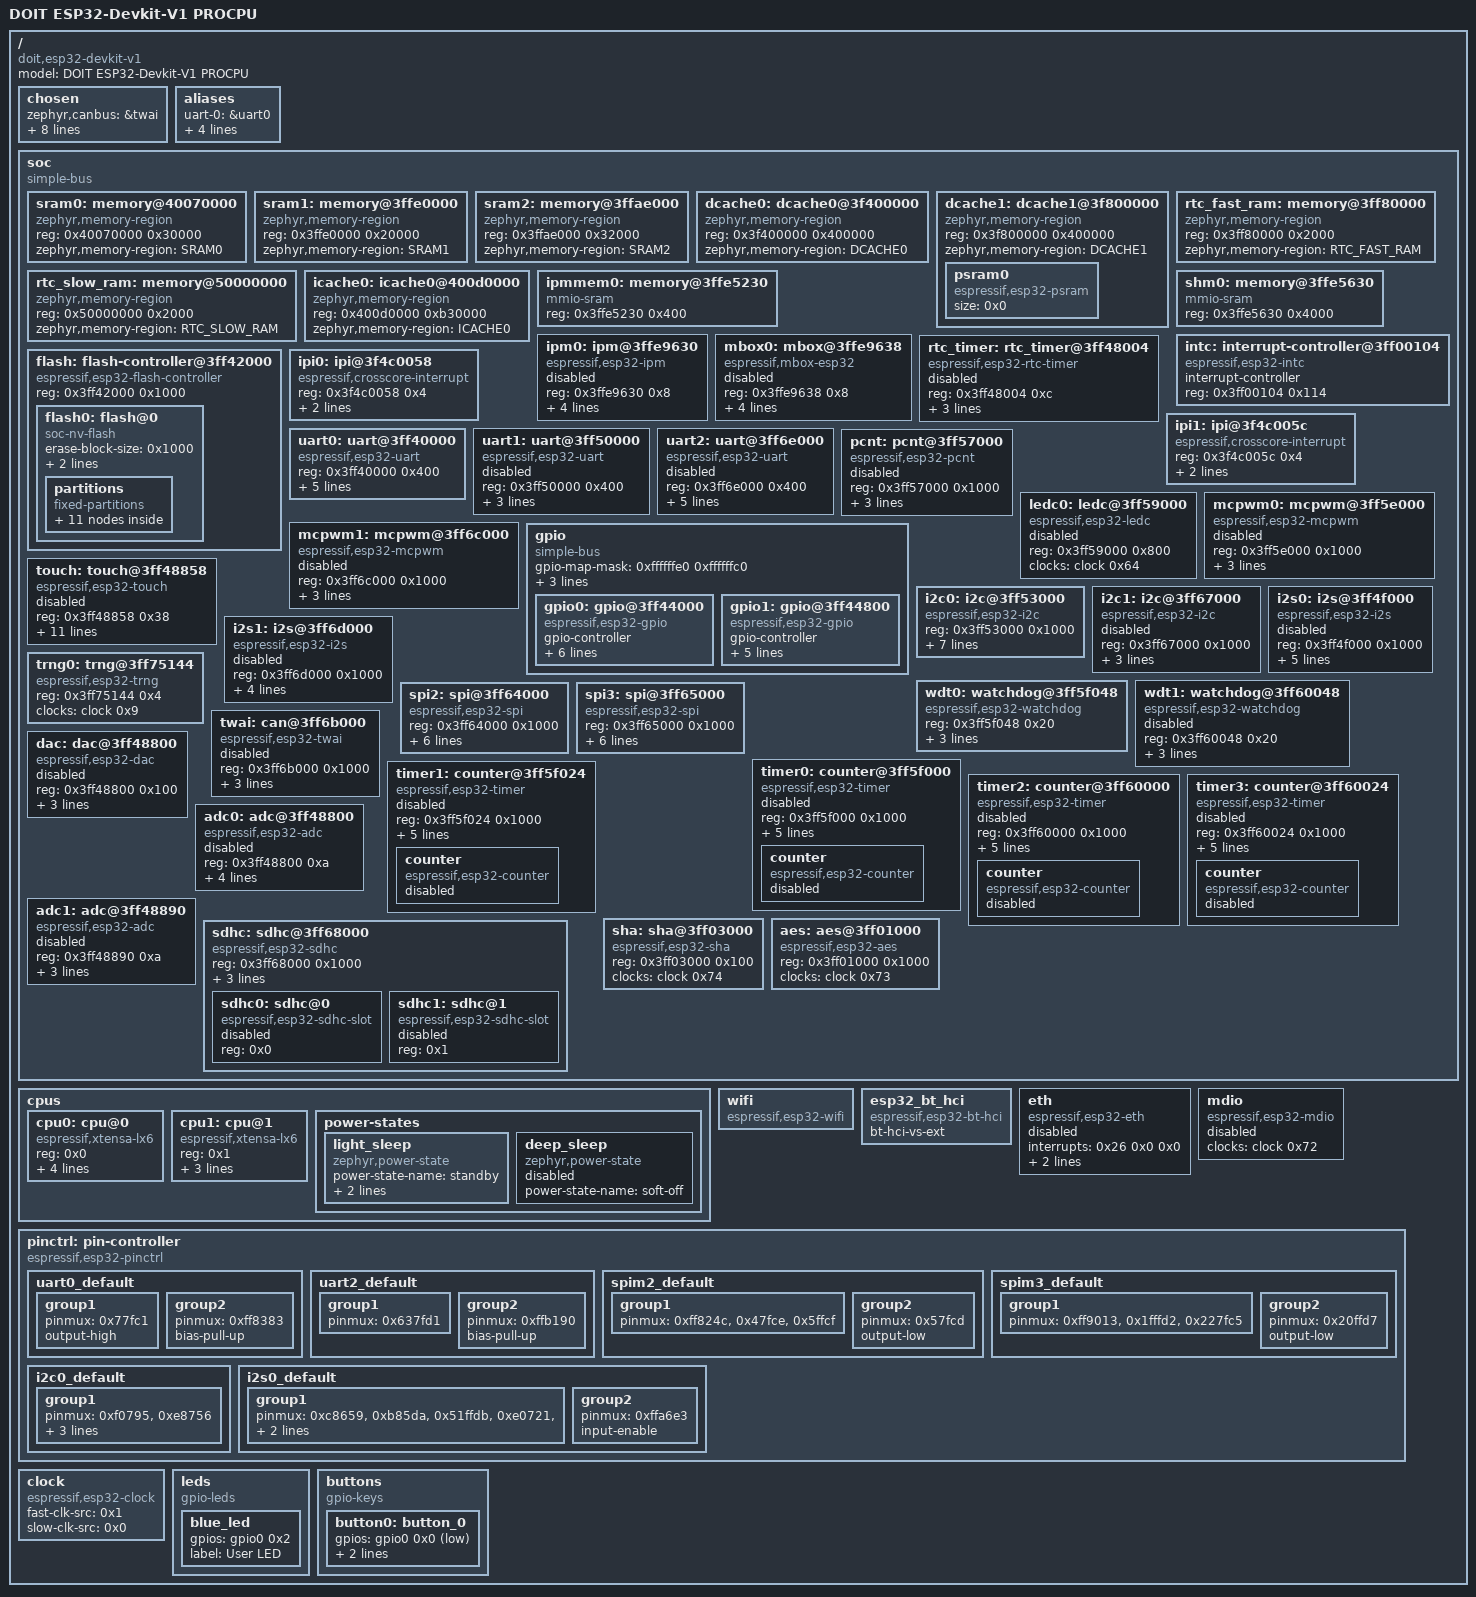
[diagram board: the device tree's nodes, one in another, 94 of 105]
/dts-v1/;

/* node '/' defined in zephyr/dts/common/skeleton.dtsi:9 */
/ {
	#address-cells = < 0x1 >;              /* in zephyr/dts/common/skeleton.dtsi:10 */
	#size-cells = < 0x1 >;                 /* in zephyr/dts/common/skeleton.dtsi:11 */
	model = "DOIT ESP32-Devkit-V1 PROCPU"; /* in zephyr/boards/others/doit_esp32_devkit_v1/doit_esp32_devkit_v1_procpu.dts:15 */
	compatible = "doit,esp32-devkit-v1";   /* in zephyr/boards/others/doit_esp32_devkit_v1/doit_esp32_devkit_v1_procpu.dts:16 */

	/* node '/chosen' defined in zephyr/dts/common/skeleton.dtsi:13 */
	chosen {
		zephyr,canbus = &twai;                    /* in zephyr/dts/xtensa/espressif/esp32/esp32_common.dtsi:20 */
		zephyr,entropy = &trng0;                  /* in zephyr/dts/xtensa/espressif/esp32/esp32_common.dtsi:21 */
		zephyr,flash-controller = &flash;         /* in zephyr/dts/xtensa/espressif/esp32/esp32_common.dtsi:22 */
		zephyr,sram = &sram1;                     /* in zephyr/boards/others/doit_esp32_devkit_v1/doit_esp32_devkit_v1_procpu.dts:46 */
		zephyr,console = &uart0;                  /* in zephyr/boards/others/doit_esp32_devkit_v1/doit_esp32_devkit_v1_procpu.dts:47 */
		zephyr,shell-uart = &uart0;               /* in zephyr/boards/others/doit_esp32_devkit_v1/doit_esp32_devkit_v1_procpu.dts:48 */
		zephyr,flash = &flash0;                   /* in zephyr/boards/others/doit_esp32_devkit_v1/doit_esp32_devkit_v1_procpu.dts:49 */
		zephyr,code-partition = &slot0_partition; /* in zephyr/boards/others/doit_esp32_devkit_v1/doit_esp32_devkit_v1_procpu.dts:50 */
		zephyr,bt-hci = &esp32_bt_hci;            /* in zephyr/boards/others/doit_esp32_devkit_v1/doit_esp32_devkit_v1_procpu.dts:51 */
	};

	/* node '/aliases' defined in zephyr/dts/common/skeleton.dtsi:15 */
	aliases {
		uart-0 = &uart0;   /* in zephyr/boards/others/doit_esp32_devkit_v1/doit_esp32_devkit_v1_procpu.dts:19 */
		i2c-0 = &i2c0;     /* in zephyr/boards/others/doit_esp32_devkit_v1/doit_esp32_devkit_v1_procpu.dts:20 */
		sw0 = &button0;    /* in zephyr/boards/others/doit_esp32_devkit_v1/doit_esp32_devkit_v1_procpu.dts:21 */
		led0 = &blue_led;  /* in zephyr/boards/others/doit_esp32_devkit_v1/doit_esp32_devkit_v1_procpu.dts:22 */
		watchdog0 = &wdt0; /* in zephyr/boards/others/doit_esp32_devkit_v1/doit_esp32_devkit_v1_procpu.dts:23 */
	};

	/* node '/soc' defined in zephyr/dts/xtensa/xtensa.dtsi:10 */
	soc {
		#address-cells = < 0x1 >;  /* in zephyr/dts/xtensa/xtensa.dtsi:11 */
		#size-cells = < 0x1 >;     /* in zephyr/dts/xtensa/xtensa.dtsi:12 */
		compatible = "simple-bus"; /* in zephyr/dts/xtensa/xtensa.dtsi:13 */
		ranges;                    /* in zephyr/dts/xtensa/xtensa.dtsi:14 */

		/* node '/soc/memory@40070000' defined in zephyr/dts/xtensa/espressif/esp32/esp32_common.dtsi:109 */
		sram0: memory@40070000 {
			compatible = "zephyr,memory-region",
			             "mmio-sram";            /* in zephyr/dts/xtensa/espressif/esp32/esp32_common.dtsi:110 */
			reg = < 0x40070000 0x30000 >;        /* in zephyr/dts/xtensa/espressif/esp32/esp32_common.dtsi:111 */
			zephyr,memory-region = "SRAM0";      /* in zephyr/dts/xtensa/espressif/esp32/esp32_common.dtsi:112 */
		};

		/* node '/soc/memory@3ffe0000' defined in zephyr/dts/xtensa/espressif/esp32/esp32_common.dtsi:115 */
		sram1: memory@3ffe0000 {
			compatible = "zephyr,memory-region",
			             "mmio-sram";            /* in zephyr/dts/xtensa/espressif/esp32/esp32_common.dtsi:116 */
			reg = < 0x3ffe0000 0x20000 >;        /* in zephyr/dts/xtensa/espressif/esp32/esp32_common.dtsi:117 */
			zephyr,memory-region = "SRAM1";      /* in zephyr/dts/xtensa/espressif/esp32/esp32_common.dtsi:118 */
		};

		/* node '/soc/memory@3ffae000' defined in zephyr/dts/xtensa/espressif/esp32/esp32_common.dtsi:121 */
		sram2: memory@3ffae000 {
			compatible = "zephyr,memory-region",
			             "mmio-sram";            /* in zephyr/dts/xtensa/espressif/esp32/esp32_common.dtsi:122 */
			reg = < 0x3ffae000 0x32000 >;        /* in zephyr/dts/xtensa/espressif/esp32/esp32_common.dtsi:123 */
			zephyr,memory-region = "SRAM2";      /* in zephyr/dts/xtensa/espressif/esp32/esp32_common.dtsi:124 */
		};

		/* node '/soc/dcache0@3f400000' defined in zephyr/dts/xtensa/espressif/esp32/esp32_common.dtsi:127 */
		dcache0: dcache0@3f400000 {
			compatible = "zephyr,memory-region",
			             "mmio-sram";            /* in zephyr/dts/xtensa/espressif/esp32/esp32_common.dtsi:128 */
			reg = < 0x3f400000 0x400000 >;       /* in zephyr/dts/xtensa/espressif/esp32/esp32_common.dtsi:129 */
			zephyr,memory-region = "DCACHE0";    /* in zephyr/dts/xtensa/espressif/esp32/esp32_common.dtsi:130 */
		};

		/* node '/soc/dcache1@3f800000' defined in zephyr/dts/xtensa/espressif/esp32/esp32_common.dtsi:133 */
		dcache1: dcache1@3f800000 {
			compatible = "zephyr,memory-region",
			             "mmio-sram";            /* in zephyr/dts/xtensa/espressif/esp32/esp32_common.dtsi:134 */
			reg = < 0x3f800000 0x400000 >;       /* in zephyr/dts/xtensa/espressif/esp32/esp32_common.dtsi:135 */
			zephyr,memory-region = "DCACHE1";    /* in zephyr/dts/xtensa/espressif/esp32/esp32_common.dtsi:136 */

			/* node '/soc/dcache1@3f800000/psram0' defined in zephyr/dts/xtensa/espressif/esp32/esp32_common.dtsi:138 */
			psram0: psram0 {
				compatible = "espressif,esp32-psram"; /* in zephyr/dts/xtensa/espressif/esp32/esp32_common.dtsi:139 */
				size = < 0x0 >;                       /* in zephyr/dts/xtensa/espressif/esp32/esp32_common.dtsi:140 */
			};
		};

		/* node '/soc/memory@3ff80000' defined in zephyr/dts/xtensa/espressif/esp32/esp32_common.dtsi:144 */
		rtc_fast_ram: memory@3ff80000 {
			compatible = "zephyr,memory-region",
			             "mmio-sram";              /* in zephyr/dts/xtensa/espressif/esp32/esp32_common.dtsi:145 */
			reg = < 0x3ff80000 0x2000 >;           /* in zephyr/dts/xtensa/espressif/esp32/esp32_common.dtsi:146 */
			zephyr,memory-region = "RTC_FAST_RAM"; /* in zephyr/dts/xtensa/espressif/esp32/esp32_common.dtsi:147 */
		};

		/* node '/soc/memory@50000000' defined in zephyr/dts/xtensa/espressif/esp32/esp32_common.dtsi:150 */
		rtc_slow_ram: memory@50000000 {
			compatible = "zephyr,memory-region",
			             "mmio-sram";              /* in zephyr/dts/xtensa/espressif/esp32/esp32_common.dtsi:151 */
			reg = < 0x50000000 0x2000 >;           /* in zephyr/dts/xtensa/espressif/esp32/esp32_common.dtsi:152 */
			zephyr,memory-region = "RTC_SLOW_RAM"; /* in zephyr/dts/xtensa/espressif/esp32/esp32_common.dtsi:153 */
		};

		/* node '/soc/icache0@400d0000' defined in zephyr/dts/xtensa/espressif/esp32/esp32_common.dtsi:156 */
		icache0: icache0@400d0000 {
			compatible = "zephyr,memory-region",
			             "mmio-sram";            /* in zephyr/dts/xtensa/espressif/esp32/esp32_common.dtsi:157 */
			reg = < 0x400d0000 0xb30000 >;       /* in zephyr/dts/xtensa/espressif/esp32/esp32_common.dtsi:158 */
			zephyr,memory-region = "ICACHE0";    /* in zephyr/dts/xtensa/espressif/esp32/esp32_common.dtsi:159 */
		};

		/* node '/soc/memory@3ffe5230' defined in zephyr/dts/xtensa/espressif/esp32/esp32_common.dtsi:162 */
		ipmmem0: memory@3ffe5230 {
			compatible = "mmio-sram";   /* in zephyr/dts/xtensa/espressif/esp32/esp32_common.dtsi:163 */
			reg = < 0x3ffe5230 0x400 >; /* in zephyr/dts/xtensa/espressif/esp32/esp32_common.dtsi:164 */
			phandle = < 0x1 >;          /* in zephyr/dts/xtensa/espressif/esp32/esp32_common.dtsi:176 */
		};

		/* node '/soc/memory@3ffe5630' defined in zephyr/dts/xtensa/espressif/esp32/esp32_common.dtsi:167 */
		shm0: memory@3ffe5630 {
			compatible = "mmio-sram";    /* in zephyr/dts/xtensa/espressif/esp32/esp32_common.dtsi:168 */
			reg = < 0x3ffe5630 0x4000 >; /* in zephyr/dts/xtensa/espressif/esp32/esp32_common.dtsi:169 */
		};

		/* node '/soc/ipm@3ffe9630' defined in zephyr/dts/xtensa/espressif/esp32/esp32_common.dtsi:172 */
		ipm0: ipm@3ffe9630 {
			compatible = "espressif,esp32-ipm"; /* in zephyr/dts/xtensa/espressif/esp32/esp32_common.dtsi:173 */
			reg = < 0x3ffe9630 0x8 >;           /* in zephyr/dts/xtensa/espressif/esp32/esp32_common.dtsi:174 */
			status = "disabled";                /* in zephyr/dts/xtensa/espressif/esp32/esp32_common.dtsi:175 */
			shared-memory = < &ipmmem0 >;       /* in zephyr/dts/xtensa/espressif/esp32/esp32_common.dtsi:176 */
			shared-memory-size = < 0x400 >;     /* in zephyr/dts/xtensa/espressif/esp32/esp32_common.dtsi:177 */
			interrupts = < 0x18 0x0 0x0 >,
			             < 0x19 0x0 0x0 >;      /* in zephyr/dts/xtensa/espressif/esp32/esp32_common.dtsi:178 */
			interrupt-parent = < &intc >;       /* in zephyr/dts/xtensa/espressif/esp32/esp32_common.dtsi:180 */
		};

		/* node '/soc/mbox@3ffe9638' defined in zephyr/dts/xtensa/espressif/esp32/esp32_common.dtsi:183 */
		mbox0: mbox@3ffe9638 {
			compatible = "espressif,mbox-esp32"; /* in zephyr/dts/xtensa/espressif/esp32/esp32_common.dtsi:184 */
			reg = < 0x3ffe9638 0x8 >;            /* in zephyr/dts/xtensa/espressif/esp32/esp32_common.dtsi:185 */
			status = "disabled";                 /* in zephyr/dts/xtensa/espressif/esp32/esp32_common.dtsi:186 */
			shared-memory = < &ipmmem0 >;        /* in zephyr/dts/xtensa/espressif/esp32/esp32_common.dtsi:187 */
			shared-memory-size = < 0x400 >;      /* in zephyr/dts/xtensa/espressif/esp32/esp32_common.dtsi:188 */
			interrupts = < 0x18 0x0 0x0 >,
			             < 0x19 0x0 0x0 >;       /* in zephyr/dts/xtensa/espressif/esp32/esp32_common.dtsi:189 */
			interrupt-parent = < &intc >;        /* in zephyr/dts/xtensa/espressif/esp32/esp32_common.dtsi:191 */
			#mbox-cells = < 0x1 >;               /* in zephyr/dts/xtensa/espressif/esp32/esp32_common.dtsi:192 */
		};

		/* node '/soc/interrupt-controller@3ff00104' defined in zephyr/dts/xtensa/espressif/esp32/esp32_common.dtsi:195 */
		intc: interrupt-controller@3ff00104 {
			#interrupt-cells = < 0x3 >;          /* in zephyr/dts/xtensa/espressif/esp32/esp32_common.dtsi:196 */
			#address-cells = < 0x0 >;            /* in zephyr/dts/xtensa/espressif/esp32/esp32_common.dtsi:197 */
			compatible = "espressif,esp32-intc"; /* in zephyr/dts/xtensa/espressif/esp32/esp32_common.dtsi:198 */
			interrupt-controller;                /* in zephyr/dts/xtensa/espressif/esp32/esp32_common.dtsi:199 */
			reg = < 0x3ff00104 0x114 >;          /* in zephyr/dts/xtensa/espressif/esp32/esp32_common.dtsi:200 */
			status = "okay";                     /* in zephyr/dts/xtensa/espressif/esp32/esp32_common.dtsi:201 */
			phandle = < 0x2 >;                   /* in zephyr/dts/xtensa/espressif/esp32/esp32_common.dtsi:180 */
		};

		/* node '/soc/rtc_timer@3ff48004' defined in zephyr/dts/xtensa/espressif/esp32/esp32_common.dtsi:204 */
		rtc_timer: rtc_timer@3ff48004 {
			reg = < 0x3ff48004 0xc >;                 /* in zephyr/dts/xtensa/espressif/esp32/esp32_common.dtsi:205 */
			compatible = "espressif,esp32-rtc-timer"; /* in zephyr/dts/xtensa/espressif/esp32/esp32_common.dtsi:206 */
			clocks = < &clock 0xf >;                  /* in zephyr/dts/xtensa/espressif/esp32/esp32_common.dtsi:207 */
			interrupts = < 0x2e 0x0 0x0 >;            /* in zephyr/dts/xtensa/espressif/esp32/esp32_common.dtsi:208 */
			interrupt-parent = < &intc >;             /* in zephyr/dts/xtensa/espressif/esp32/esp32_common.dtsi:209 */
			status = "disabled";                      /* in zephyr/dts/xtensa/espressif/esp32/esp32_common.dtsi:210 */
		};

		/* node '/soc/flash-controller@3ff42000' defined in zephyr/dts/xtensa/espressif/esp32/esp32_common.dtsi:213 */
		flash: flash-controller@3ff42000 {
			compatible = "espressif,esp32-flash-controller"; /* in zephyr/dts/xtensa/espressif/esp32/esp32_common.dtsi:214 */
			reg = < 0x3ff42000 0x1000 >;                     /* in zephyr/dts/xtensa/espressif/esp32/esp32_common.dtsi:215 */
			#address-cells = < 0x1 >;                        /* in zephyr/dts/xtensa/espressif/esp32/esp32_common.dtsi:216 */
			#size-cells = < 0x1 >;                           /* in zephyr/dts/xtensa/espressif/esp32/esp32_common.dtsi:217 */

			/* node '/soc/flash-controller@3ff42000/flash@0' defined in zephyr/dts/xtensa/espressif/esp32/esp32_common.dtsi:219 */
			flash0: flash@0 {
				compatible = "soc-nv-flash";   /* in zephyr/dts/xtensa/espressif/esp32/esp32_common.dtsi:220 */
				erase-block-size = < 0x1000 >; /* in zephyr/dts/xtensa/espressif/esp32/esp32_common.dtsi:221 */
				write-block-size = < 0x4 >;    /* in zephyr/dts/xtensa/espressif/esp32/esp32_common.dtsi:222 */
				reg = < 0x0 0x400000 >;        /* in zephyr/dts/xtensa/espressif/esp32/esp32_wroom_32ue_n4.dtsi:21 */

				/* node '/soc/flash-controller@3ff42000/flash@0/partitions' defined in zephyr/dts/vendor/espressif/partitions_0x1000_amp_4M.dtsi:8 */
				partitions {
					compatible = "fixed-partitions"; /* in zephyr/dts/vendor/espressif/partitions_0x1000_amp_4M.dtsi:9 */
					#address-cells = < 0x1 >;        /* in zephyr/dts/vendor/espressif/partitions_0x1000_amp_4M.dtsi:10 */
					#size-cells = < 0x1 >;           /* in zephyr/dts/vendor/espressif/partitions_0x1000_amp_4M.dtsi:11 */

					/* node '/soc/flash-controller@3ff42000/flash@0/partitions/partition@1000' defined in zephyr/dts/vendor/espressif/partitions_0x1000_amp_4M.dtsi:13 */
					boot_partition: partition@1000 {
						label = "mcuboot";       /* in zephyr/dts/vendor/espressif/partitions_0x1000_amp_4M.dtsi:14 */
						reg = < 0x1000 0xf000 >; /* in zephyr/dts/vendor/espressif/partitions_0x1000_amp_4M.dtsi:15 */
					};

					/* node '/soc/flash-controller@3ff42000/flash@0/partitions/partition@10000' defined in zephyr/dts/vendor/espressif/partitions_0x1000_amp_4M.dtsi:18 */
					sys_partition: partition@10000 {
						label = "sys";             /* in zephyr/dts/vendor/espressif/partitions_0x1000_amp_4M.dtsi:19 */
						reg = < 0x10000 0x10000 >; /* in zephyr/dts/vendor/espressif/partitions_0x1000_amp_4M.dtsi:20 */
					};

					/* node '/soc/flash-controller@3ff42000/flash@0/partitions/partition@20000' defined in zephyr/dts/vendor/espressif/partitions_0x1000_amp_4M.dtsi:23 */
					slot0_partition: partition@20000 {
						label = "image-0";          /* in zephyr/dts/vendor/espressif/partitions_0x1000_amp_4M.dtsi:24 */
						reg = < 0x20000 0x150000 >; /* in zephyr/dts/vendor/espressif/partitions_0x1000_amp_4M.dtsi:25 */
					};

					/* node '/soc/flash-controller@3ff42000/flash@0/partitions/partition@170000' defined in zephyr/dts/vendor/espressif/partitions_0x1000_amp_4M.dtsi:28 */
					slot1_partition: partition@170000 {
						label = "image-1";           /* in zephyr/dts/vendor/espressif/partitions_0x1000_amp_4M.dtsi:29 */
						reg = < 0x170000 0x150000 >; /* in zephyr/dts/vendor/espressif/partitions_0x1000_amp_4M.dtsi:30 */
					};

					/* node '/soc/flash-controller@3ff42000/flash@0/partitions/partition@2c0000' defined in zephyr/dts/vendor/espressif/partitions_0x1000_amp_4M.dtsi:33 */
					slot0_appcpu_partition: partition@2c0000 {
						label = "image-0-appcpu";   /* in zephyr/dts/vendor/espressif/partitions_0x1000_amp_4M.dtsi:34 */
						reg = < 0x2c0000 0x70000 >; /* in zephyr/dts/vendor/espressif/partitions_0x1000_amp_4M.dtsi:35 */
					};

					/* node '/soc/flash-controller@3ff42000/flash@0/partitions/partition@330000' defined in zephyr/dts/vendor/espressif/partitions_0x1000_amp_4M.dtsi:38 */
					slot1_appcpu_partition: partition@330000 {
						label = "image-1-appcpu";   /* in zephyr/dts/vendor/espressif/partitions_0x1000_amp_4M.dtsi:39 */
						reg = < 0x330000 0x70000 >; /* in zephyr/dts/vendor/espressif/partitions_0x1000_amp_4M.dtsi:40 */
					};

					/* node '/soc/flash-controller@3ff42000/flash@0/partitions/partition@3a0000' defined in zephyr/dts/vendor/espressif/partitions_0x1000_amp_4M.dtsi:43 */
					slot0_lpcore_partition: partition@3a0000 {
						label = "image-0-lpcore";  /* in zephyr/dts/vendor/espressif/partitions_0x1000_amp_4M.dtsi:44 */
						reg = < 0x3a0000 0x8000 >; /* in zephyr/dts/vendor/espressif/partitions_0x1000_amp_4M.dtsi:45 */
					};

					/* node '/soc/flash-controller@3ff42000/flash@0/partitions/partition@3a8000' defined in zephyr/dts/vendor/espressif/partitions_0x1000_amp_4M.dtsi:48 */
					slot1_lpcore_partition: partition@3a8000 {
						label = "image-1-lpcore";  /* in zephyr/dts/vendor/espressif/partitions_0x1000_amp_4M.dtsi:49 */
						reg = < 0x3a8000 0x8000 >; /* in zephyr/dts/vendor/espressif/partitions_0x1000_amp_4M.dtsi:50 */
					};

					/* node '/soc/flash-controller@3ff42000/flash@0/partitions/partition@3b0000' defined in zephyr/dts/vendor/espressif/partitions_0x1000_amp_4M.dtsi:53 */
					storage_partition: partition@3b0000 {
						label = "storage";          /* in zephyr/dts/vendor/espressif/partitions_0x1000_amp_4M.dtsi:54 */
						reg = < 0x3b0000 0x30000 >; /* in zephyr/dts/vendor/espressif/partitions_0x1000_amp_4M.dtsi:55 */
					};

					/* node '/soc/flash-controller@3ff42000/flash@0/partitions/partition@3e0000' defined in zephyr/dts/vendor/espressif/partitions_0x1000_amp_4M.dtsi:58 */
					scratch_partition: partition@3e0000 {
						label = "image-scratch";    /* in zephyr/dts/vendor/espressif/partitions_0x1000_amp_4M.dtsi:59 */
						reg = < 0x3e0000 0x1f000 >; /* in zephyr/dts/vendor/espressif/partitions_0x1000_amp_4M.dtsi:60 */
					};

					/* node '/soc/flash-controller@3ff42000/flash@0/partitions/partition@3ff000' defined in zephyr/dts/vendor/espressif/partitions_0x1000_amp_4M.dtsi:63 */
					coredump_partition: partition@3ff000 {
						label = "coredump";        /* in zephyr/dts/vendor/espressif/partitions_0x1000_amp_4M.dtsi:64 */
						reg = < 0x3ff000 0x1000 >; /* in zephyr/dts/vendor/espressif/partitions_0x1000_amp_4M.dtsi:65 */
					};
				};
			};
		};

		/* node '/soc/ipi@3f4c0058' defined in zephyr/dts/xtensa/espressif/esp32/esp32_common.dtsi:227 */
		ipi0: ipi@3f4c0058 {
			compatible = "espressif,crosscore-interrupt"; /* in zephyr/dts/xtensa/espressif/esp32/esp32_common.dtsi:228 */
			reg = < 0x3f4c0058 0x4 >;                     /* in zephyr/dts/xtensa/espressif/esp32/esp32_common.dtsi:229 */
			interrupts = < 0x18 0x0 0x0 >;                /* in zephyr/dts/xtensa/espressif/esp32/esp32_common.dtsi:230 */
			interrupt-parent = < &intc >;                 /* in zephyr/dts/xtensa/espressif/esp32/esp32_common.dtsi:231 */
		};

		/* node '/soc/ipi@3f4c005c' defined in zephyr/dts/xtensa/espressif/esp32/esp32_common.dtsi:234 */
		ipi1: ipi@3f4c005c {
			compatible = "espressif,crosscore-interrupt"; /* in zephyr/dts/xtensa/espressif/esp32/esp32_common.dtsi:235 */
			reg = < 0x3f4c005c 0x4 >;                     /* in zephyr/dts/xtensa/espressif/esp32/esp32_common.dtsi:236 */
			interrupts = < 0x19 0x0 0x0 >;                /* in zephyr/dts/xtensa/espressif/esp32/esp32_common.dtsi:237 */
			interrupt-parent = < &intc >;                 /* in zephyr/dts/xtensa/espressif/esp32/esp32_common.dtsi:238 */
		};

		/* node '/soc/uart@3ff40000' defined in zephyr/dts/xtensa/espressif/esp32/esp32_common.dtsi:241 */
		uart0: uart@3ff40000 {
			compatible = "espressif,esp32-uart"; /* in zephyr/dts/xtensa/espressif/esp32/esp32_common.dtsi:242 */
			reg = < 0x3ff40000 0x400 >;          /* in zephyr/dts/xtensa/espressif/esp32/esp32_common.dtsi:243 */
			interrupts = < 0x22 0x0 0x0 >;       /* in zephyr/dts/xtensa/espressif/esp32/esp32_common.dtsi:244 */
			interrupt-parent = < &intc >;        /* in zephyr/dts/xtensa/espressif/esp32/esp32_common.dtsi:245 */
			clocks = < &clock 0x65 >;            /* in zephyr/dts/xtensa/espressif/esp32/esp32_common.dtsi:246 */
			status = "okay";                     /* in zephyr/boards/others/doit_esp32_devkit_v1/doit_esp32_devkit_v1_procpu.dts:56 */
			current-speed = < 0x1c200 >;         /* in zephyr/boards/others/doit_esp32_devkit_v1/doit_esp32_devkit_v1_procpu.dts:57 */
			pinctrl-0 = < &uart0_default >;      /* in zephyr/boards/others/doit_esp32_devkit_v1/doit_esp32_devkit_v1_procpu.dts:58 */
			pinctrl-names = "default";           /* in zephyr/boards/others/doit_esp32_devkit_v1/doit_esp32_devkit_v1_procpu.dts:59 */
		};

		/* node '/soc/uart@3ff50000' defined in zephyr/dts/xtensa/espressif/esp32/esp32_common.dtsi:250 */
		uart1: uart@3ff50000 {
			compatible = "espressif,esp32-uart"; /* in zephyr/dts/xtensa/espressif/esp32/esp32_common.dtsi:251 */
			reg = < 0x3ff50000 0x400 >;          /* in zephyr/dts/xtensa/espressif/esp32/esp32_common.dtsi:252 */
			interrupts = < 0x23 0x0 0x0 >;       /* in zephyr/dts/xtensa/espressif/esp32/esp32_common.dtsi:253 */
			interrupt-parent = < &intc >;        /* in zephyr/dts/xtensa/espressif/esp32/esp32_common.dtsi:254 */
			clocks = < &clock 0x0 >;             /* in zephyr/dts/xtensa/espressif/esp32/esp32_common.dtsi:255 */
			status = "disabled";                 /* in zephyr/dts/xtensa/espressif/esp32/esp32_common.dtsi:256 */
		};

		/* node '/soc/uart@3ff6e000' defined in zephyr/dts/xtensa/espressif/esp32/esp32_common.dtsi:259 */
		uart2: uart@3ff6e000 {
			compatible = "espressif,esp32-uart"; /* in zephyr/dts/xtensa/espressif/esp32/esp32_common.dtsi:260 */
			reg = < 0x3ff6e000 0x400 >;          /* in zephyr/dts/xtensa/espressif/esp32/esp32_common.dtsi:261 */
			interrupts = < 0x24 0x0 0x0 >;       /* in zephyr/dts/xtensa/espressif/esp32/esp32_common.dtsi:262 */
			interrupt-parent = < &intc >;        /* in zephyr/dts/xtensa/espressif/esp32/esp32_common.dtsi:263 */
			clocks = < &clock 0x1 >;             /* in zephyr/dts/xtensa/espressif/esp32/esp32_common.dtsi:264 */
			status = "disabled";                 /* in zephyr/dts/xtensa/espressif/esp32/esp32_common.dtsi:265 */
			current-speed = < 0x1c200 >;         /* in zephyr/boards/others/doit_esp32_devkit_v1/doit_esp32_devkit_v1_procpu.dts:63 */
			pinctrl-0 = < &uart2_default >;      /* in zephyr/boards/others/doit_esp32_devkit_v1/doit_esp32_devkit_v1_procpu.dts:64 */
			pinctrl-names = "default";           /* in zephyr/boards/others/doit_esp32_devkit_v1/doit_esp32_devkit_v1_procpu.dts:65 */
		};

		/* node '/soc/pcnt@3ff57000' defined in zephyr/dts/xtensa/espressif/esp32/esp32_common.dtsi:268 */
		pcnt: pcnt@3ff57000 {
			compatible = "espressif,esp32-pcnt"; /* in zephyr/dts/xtensa/espressif/esp32/esp32_common.dtsi:269 */
			reg = < 0x3ff57000 0x1000 >;         /* in zephyr/dts/xtensa/espressif/esp32/esp32_common.dtsi:270 */
			interrupts = < 0x30 0x0 0x0 >;       /* in zephyr/dts/xtensa/espressif/esp32/esp32_common.dtsi:271 */
			interrupt-parent = < &intc >;        /* in zephyr/dts/xtensa/espressif/esp32/esp32_common.dtsi:272 */
			clocks = < &clock 0x6d >;            /* in zephyr/dts/xtensa/espressif/esp32/esp32_common.dtsi:273 */
			status = "disabled";                 /* in zephyr/dts/xtensa/espressif/esp32/esp32_common.dtsi:274 */
		};

		/* node '/soc/ledc@3ff59000' defined in zephyr/dts/xtensa/espressif/esp32/esp32_common.dtsi:277 */
		ledc0: ledc@3ff59000 {
			compatible = "espressif,esp32-ledc"; /* in zephyr/dts/xtensa/espressif/esp32/esp32_common.dtsi:278 */
			#pwm-cells = < 0x3 >;                /* in zephyr/dts/xtensa/espressif/esp32/esp32_common.dtsi:279 */
			reg = < 0x3ff59000 0x800 >;          /* in zephyr/dts/xtensa/espressif/esp32/esp32_common.dtsi:280 */
			clocks = < &clock 0x64 >;            /* in zephyr/dts/xtensa/espressif/esp32/esp32_common.dtsi:281 */
			status = "disabled";                 /* in zephyr/dts/xtensa/espressif/esp32/esp32_common.dtsi:282 */
		};

		/* node '/soc/mcpwm@3ff5e000' defined in zephyr/dts/xtensa/espressif/esp32/esp32_common.dtsi:285 */
		mcpwm0: mcpwm@3ff5e000 {
			compatible = "espressif,esp32-mcpwm"; /* in zephyr/dts/xtensa/espressif/esp32/esp32_common.dtsi:286 */
			reg = < 0x3ff5e000 0x1000 >;          /* in zephyr/dts/xtensa/espressif/esp32/esp32_common.dtsi:287 */
			interrupts = < 0x27 0x0 0x0 >;        /* in zephyr/dts/xtensa/espressif/esp32/esp32_common.dtsi:288 */
			interrupt-parent = < &intc >;         /* in zephyr/dts/xtensa/espressif/esp32/esp32_common.dtsi:289 */
			clocks = < &clock 0x69 >;             /* in zephyr/dts/xtensa/espressif/esp32/esp32_common.dtsi:290 */
			#pwm-cells = < 0x3 >;                 /* in zephyr/dts/xtensa/espressif/esp32/esp32_common.dtsi:291 */
			status = "disabled";                  /* in zephyr/dts/xtensa/espressif/esp32/esp32_common.dtsi:292 */
		};

		/* node '/soc/mcpwm@3ff6c000' defined in zephyr/dts/xtensa/espressif/esp32/esp32_common.dtsi:295 */
		mcpwm1: mcpwm@3ff6c000 {
			compatible = "espressif,esp32-mcpwm"; /* in zephyr/dts/xtensa/espressif/esp32/esp32_common.dtsi:296 */
			reg = < 0x3ff6c000 0x1000 >;          /* in zephyr/dts/xtensa/espressif/esp32/esp32_common.dtsi:297 */
			interrupts = < 0x28 0x0 0x0 >;        /* in zephyr/dts/xtensa/espressif/esp32/esp32_common.dtsi:298 */
			interrupt-parent = < &intc >;         /* in zephyr/dts/xtensa/espressif/esp32/esp32_common.dtsi:299 */
			clocks = < &clock 0x6a >;             /* in zephyr/dts/xtensa/espressif/esp32/esp32_common.dtsi:300 */
			#pwm-cells = < 0x3 >;                 /* in zephyr/dts/xtensa/espressif/esp32/esp32_common.dtsi:301 */
			status = "disabled";                  /* in zephyr/dts/xtensa/espressif/esp32/esp32_common.dtsi:302 */
		};

		/* node '/soc/gpio' defined in zephyr/dts/xtensa/espressif/esp32/esp32_common.dtsi:305 */
		gpio: gpio {
			compatible = "simple-bus";                                     /* in zephyr/dts/xtensa/espressif/esp32/esp32_common.dtsi:306 */
			gpio-map-mask = < 0xffffffe0 0xffffffc0 >;                     /* in zephyr/dts/xtensa/espressif/esp32/esp32_common.dtsi:307 */
			gpio-map-pass-thru = < 0x1f 0x3f >;                            /* in zephyr/dts/xtensa/espressif/esp32/esp32_common.dtsi:308 */
			gpio-map = < 0x0 0x0 &gpio0 0x0 0x0 0x20 0x0 &gpio1 0x0 0x0 >; /* in zephyr/dts/xtensa/espressif/esp32/esp32_common.dtsi:309 */
			#gpio-cells = < 0x2 >;                                         /* in zephyr/dts/xtensa/espressif/esp32/esp32_common.dtsi:311 */
			#address-cells = < 0x1 >;                                      /* in zephyr/dts/xtensa/espressif/esp32/esp32_common.dtsi:312 */
			#size-cells = < 0x1 >;                                         /* in zephyr/dts/xtensa/espressif/esp32/esp32_common.dtsi:313 */
			ranges;                                                        /* in zephyr/dts/xtensa/espressif/esp32/esp32_common.dtsi:314 */

			/* node '/soc/gpio/gpio@3ff44000' defined in zephyr/dts/xtensa/espressif/esp32/esp32_common.dtsi:316 */
			gpio0: gpio@3ff44000 {
				compatible = "espressif,esp32-gpio"; /* in zephyr/dts/xtensa/espressif/esp32/esp32_common.dtsi:317 */
				gpio-controller;                     /* in zephyr/dts/xtensa/espressif/esp32/esp32_common.dtsi:318 */
				#gpio-cells = < 0x2 >;               /* in zephyr/dts/xtensa/espressif/esp32/esp32_common.dtsi:319 */
				reg = < 0x3ff44000 0x800 >;          /* in zephyr/dts/xtensa/espressif/esp32/esp32_common.dtsi:320 */
				interrupts = < 0x16 0x0 0x0 >;       /* in zephyr/dts/xtensa/espressif/esp32/esp32_common.dtsi:321 */
				interrupt-parent = < &intc >;        /* in zephyr/dts/xtensa/espressif/esp32/esp32_common.dtsi:322 */
				ngpios = < 0x20 >;                   /* in zephyr/dts/xtensa/espressif/esp32/esp32_common.dtsi:328 */
				gpio-reserved-ranges = < 0x6 0x6 >,
				                       < 0x14 0x1 >,
				                       < 0x18 0x1 >,
				                       < 0x1c 0x4 >; /* in zephyr/dts/xtensa/espressif/esp32/esp32_wroom_32ue_n4.dtsi:11 */
				status = "okay";                     /* in zephyr/boards/others/doit_esp32_devkit_v1/doit_esp32_devkit_v1_procpu.dts:69 */
				phandle = < 0x6 >;                   /* in zephyr/dts/xtensa/espressif/esp32/esp32_common.dtsi:309 */
			};

			/* node '/soc/gpio/gpio@3ff44800' defined in zephyr/dts/xtensa/espressif/esp32/esp32_common.dtsi:331 */
			gpio1: gpio@3ff44800 {
				compatible = "espressif,esp32-gpio"; /* in zephyr/dts/xtensa/espressif/esp32/esp32_common.dtsi:332 */
				gpio-controller;                     /* in zephyr/dts/xtensa/espressif/esp32/esp32_common.dtsi:333 */
				#gpio-cells = < 0x2 >;               /* in zephyr/dts/xtensa/espressif/esp32/esp32_common.dtsi:334 */
				reg = < 0x3ff44800 0x800 >;          /* in zephyr/dts/xtensa/espressif/esp32/esp32_common.dtsi:335 */
				interrupts = < 0x16 0x0 0x0 >;       /* in zephyr/dts/xtensa/espressif/esp32/esp32_common.dtsi:336 */
				interrupt-parent = < &intc >;        /* in zephyr/dts/xtensa/espressif/esp32/esp32_common.dtsi:337 */
				ngpios = < 0x8 >;                    /* in zephyr/dts/xtensa/espressif/esp32/esp32_common.dtsi:338 */
				gpio-reserved-ranges = < 0x5 0x2 >;  /* in zephyr/dts/xtensa/espressif/esp32/esp32_wroom_32ue_n4.dtsi:16 */
				status = "okay";                     /* in zephyr/boards/others/doit_esp32_devkit_v1/doit_esp32_devkit_v1_procpu.dts:73 */
				phandle = < 0x7 >;                   /* in zephyr/dts/xtensa/espressif/esp32/esp32_common.dtsi:309 */
			};
		};

		/* node '/soc/touch@3ff48858' defined in zephyr/dts/xtensa/espressif/esp32/esp32_common.dtsi:342 */
		touch: touch@3ff48858 {
			compatible = "espressif,esp32-touch"; /* in zephyr/dts/xtensa/espressif/esp32/esp32_common.dtsi:343 */
			reg = < 0x3ff48858 0x38 >;            /* in zephyr/dts/xtensa/espressif/esp32/esp32_common.dtsi:344 */
			interrupts = < 0x2e 0x0 0x0 >;        /* in zephyr/dts/xtensa/espressif/esp32/esp32_common.dtsi:345 */
			interrupt-parent = < &intc >;         /* in zephyr/dts/xtensa/espressif/esp32/esp32_common.dtsi:346 */
			status = "disabled";                  /* in zephyr/dts/xtensa/espressif/esp32/esp32_common.dtsi:347 */
			debounce-interval-ms = < 0x1e >;      /* in zephyr/boards/others/doit_esp32_devkit_v1/doit_esp32_devkit_v1_procpu.dts:77 */
			href-microvolt = < 0x2932e0 >;        /* in zephyr/boards/others/doit_esp32_devkit_v1/doit_esp32_devkit_v1_procpu.dts:78 */
			lref-microvolt = < 0x7a120 >;         /* in zephyr/boards/others/doit_esp32_devkit_v1/doit_esp32_devkit_v1_procpu.dts:79 */
			href-atten-microvolt = < 0xf4240 >;   /* in zephyr/boards/others/doit_esp32_devkit_v1/doit_esp32_devkit_v1_procpu.dts:80 */
			filter-mode = < 0x2 >;                /* in zephyr/boards/others/doit_esp32_devkit_v1/doit_esp32_devkit_v1_procpu.dts:81 */
			filter-debounce-cnt = < 0x1 >;        /* in zephyr/boards/others/doit_esp32_devkit_v1/doit_esp32_devkit_v1_procpu.dts:82 */
			filter-noise-thr = < 0x0 >;           /* in zephyr/boards/others/doit_esp32_devkit_v1/doit_esp32_devkit_v1_procpu.dts:83 */
			filter-jitter-step = < 0x4 >;         /* in zephyr/boards/others/doit_esp32_devkit_v1/doit_esp32_devkit_v1_procpu.dts:84 */
			filter-smooth-level = < 0x1 >;        /* in zephyr/boards/others/doit_esp32_devkit_v1/doit_esp32_devkit_v1_procpu.dts:85 */
		};

		/* node '/soc/i2c@3ff53000' defined in zephyr/dts/xtensa/espressif/esp32/esp32_common.dtsi:350 */
		i2c0: i2c@3ff53000 {
			compatible = "espressif,esp32-i2c"; /* in zephyr/dts/xtensa/espressif/esp32/esp32_common.dtsi:351 */
			#address-cells = < 0x1 >;           /* in zephyr/dts/xtensa/espressif/esp32/esp32_common.dtsi:352 */
			#size-cells = < 0x0 >;              /* in zephyr/dts/xtensa/espressif/esp32/esp32_common.dtsi:353 */
			reg = < 0x3ff53000 0x1000 >;        /* in zephyr/dts/xtensa/espressif/esp32/esp32_common.dtsi:354 */
			interrupts = < 0x31 0x0 0x0 >;      /* in zephyr/dts/xtensa/espressif/esp32/esp32_common.dtsi:355 */
			interrupt-parent = < &intc >;       /* in zephyr/dts/xtensa/espressif/esp32/esp32_common.dtsi:356 */
			clocks = < &clock 0x66 >;           /* in zephyr/dts/xtensa/espressif/esp32/esp32_common.dtsi:357 */
			status = "okay";                    /* in zephyr/boards/others/doit_esp32_devkit_v1/doit_esp32_devkit_v1_procpu.dts:89 */
			clock-frequency = < 0x186a0 >;      /* in zephyr/boards/others/doit_esp32_devkit_v1/doit_esp32_devkit_v1_procpu.dts:90 */
			sda-gpios = < &gpio0 0x15 0x6 >;    /* in zephyr/boards/others/doit_esp32_devkit_v1/doit_esp32_devkit_v1_procpu.dts:91 */
			scl-gpios = < &gpio0 0x16 0x6 >;    /* in zephyr/boards/others/doit_esp32_devkit_v1/doit_esp32_devkit_v1_procpu.dts:92 */
			pinctrl-0 = < &i2c0_default >;      /* in zephyr/boards/others/doit_esp32_devkit_v1/doit_esp32_devkit_v1_procpu.dts:93 */
			pinctrl-names = "default";          /* in zephyr/boards/others/doit_esp32_devkit_v1/doit_esp32_devkit_v1_procpu.dts:94 */
		};

		/* node '/soc/i2c@3ff67000' defined in zephyr/dts/xtensa/espressif/esp32/esp32_common.dtsi:361 */
		i2c1: i2c@3ff67000 {
			compatible = "espressif,esp32-i2c"; /* in zephyr/dts/xtensa/espressif/esp32/esp32_common.dtsi:362 */
			#address-cells = < 0x1 >;           /* in zephyr/dts/xtensa/espressif/esp32/esp32_common.dtsi:363 */
			#size-cells = < 0x0 >;              /* in zephyr/dts/xtensa/espressif/esp32/esp32_common.dtsi:364 */
			reg = < 0x3ff67000 0x1000 >;        /* in zephyr/dts/xtensa/espressif/esp32/esp32_common.dtsi:365 */
			interrupts = < 0x32 0x0 0x0 >;      /* in zephyr/dts/xtensa/espressif/esp32/esp32_common.dtsi:366 */
			interrupt-parent = < &intc >;       /* in zephyr/dts/xtensa/espressif/esp32/esp32_common.dtsi:367 */
			clocks = < &clock 0x67 >;           /* in zephyr/dts/xtensa/espressif/esp32/esp32_common.dtsi:368 */
			status = "disabled";                /* in zephyr/dts/xtensa/espressif/esp32/esp32_common.dtsi:369 */
		};

		/* node '/soc/i2s@3ff4f000' defined in zephyr/dts/xtensa/espressif/esp32/esp32_common.dtsi:372 */
		i2s0: i2s@3ff4f000 {
			compatible = "espressif,esp32-i2s"; /* in zephyr/dts/xtensa/espressif/esp32/esp32_common.dtsi:373 */
			#address-cells = < 0x1 >;           /* in zephyr/dts/xtensa/espressif/esp32/esp32_common.dtsi:374 */
			#size-cells = < 0x0 >;              /* in zephyr/dts/xtensa/espressif/esp32/esp32_common.dtsi:375 */
			reg = < 0x3ff4f000 0x1000 >;        /* in zephyr/dts/xtensa/espressif/esp32/esp32_common.dtsi:376 */
			interrupts = < 0x20 0x0 0x0 >,
			             < 0x20 0x0 0x0 >;      /* in zephyr/dts/xtensa/espressif/esp32/esp32_common.dtsi:377 */
			interrupt-names = "rx",
			                  "tx";             /* in zephyr/dts/xtensa/espressif/esp32/esp32_common.dtsi:379 */
			interrupt-parent = < &intc >;       /* in zephyr/dts/xtensa/espressif/esp32/esp32_common.dtsi:380 */
			clocks = < &clock 0x2 >;            /* in zephyr/dts/xtensa/espressif/esp32/esp32_common.dtsi:381 */
			unit = < 0x0 >;                     /* in zephyr/dts/xtensa/espressif/esp32/esp32_common.dtsi:382 */
			pinctrl-0 = < &i2s0_default >;      /* in zephyr/boards/others/doit_esp32_devkit_v1/doit_esp32_devkit_v1_procpu.dts:98 */
			pinctrl-names = "default";          /* in zephyr/boards/others/doit_esp32_devkit_v1/doit_esp32_devkit_v1_procpu.dts:99 */
			status = "disabled";                /* in zephyr/boards/others/doit_esp32_devkit_v1/doit_esp32_devkit_v1_procpu.dts:100 */
		};

		/* node '/soc/i2s@3ff6d000' defined in zephyr/dts/xtensa/espressif/esp32/esp32_common.dtsi:386 */
		i2s1: i2s@3ff6d000 {
			compatible = "espressif,esp32-i2s"; /* in zephyr/dts/xtensa/espressif/esp32/esp32_common.dtsi:387 */
			#address-cells = < 0x1 >;           /* in zephyr/dts/xtensa/espressif/esp32/esp32_common.dtsi:388 */
			#size-cells = < 0x0 >;              /* in zephyr/dts/xtensa/espressif/esp32/esp32_common.dtsi:389 */
			reg = < 0x3ff6d000 0x1000 >;        /* in zephyr/dts/xtensa/espressif/esp32/esp32_common.dtsi:390 */
			interrupts = < 0x21 0x0 0x0 >,
			             < 0x21 0x0 0x0 >;      /* in zephyr/dts/xtensa/espressif/esp32/esp32_common.dtsi:391 */
			interrupt-names = "rx",
			                  "tx";             /* in zephyr/dts/xtensa/espressif/esp32/esp32_common.dtsi:393 */
			interrupt-parent = < &intc >;       /* in zephyr/dts/xtensa/espressif/esp32/esp32_common.dtsi:394 */
			clocks = < &clock 0x68 >;           /* in zephyr/dts/xtensa/espressif/esp32/esp32_common.dtsi:395 */
			unit = < 0x1 >;                     /* in zephyr/dts/xtensa/espressif/esp32/esp32_common.dtsi:396 */
			status = "disabled";                /* in zephyr/dts/xtensa/espressif/esp32/esp32_common.dtsi:397 */
		};

		/* node '/soc/trng@3ff75144' defined in zephyr/dts/xtensa/espressif/esp32/esp32_common.dtsi:400 */
		trng0: trng@3ff75144 {
			compatible = "espressif,esp32-trng"; /* in zephyr/dts/xtensa/espressif/esp32/esp32_common.dtsi:401 */
			reg = < 0x3ff75144 0x4 >;            /* in zephyr/dts/xtensa/espressif/esp32/esp32_common.dtsi:402 */
			clocks = < &clock 0x9 >;             /* in zephyr/dts/xtensa/espressif/esp32/esp32_common.dtsi:403 */
			status = "okay";                     /* in zephyr/boards/others/doit_esp32_devkit_v1/doit_esp32_devkit_v1_procpu.dts:120 */
		};

		/* node '/soc/watchdog@3ff5f048' defined in zephyr/dts/xtensa/espressif/esp32/esp32_common.dtsi:407 */
		wdt0: watchdog@3ff5f048 {
			compatible = "espressif,esp32-watchdog"; /* in zephyr/dts/xtensa/espressif/esp32/esp32_common.dtsi:408 */
			reg = < 0x3ff5f048 0x20 >;               /* in zephyr/dts/xtensa/espressif/esp32/esp32_common.dtsi:409 */
			interrupts = < 0x10 0x0 0x0 >;           /* in zephyr/dts/xtensa/espressif/esp32/esp32_common.dtsi:410 */
			interrupt-parent = < &intc >;            /* in zephyr/dts/xtensa/espressif/esp32/esp32_common.dtsi:411 */
			clocks = < &clock 0x3 >;                 /* in zephyr/dts/xtensa/espressif/esp32/esp32_common.dtsi:412 */
			status = "okay";                         /* in zephyr/dts/xtensa/espressif/esp32/esp32_common.dtsi:413 */
		};

		/* node '/soc/watchdog@3ff60048' defined in zephyr/dts/xtensa/espressif/esp32/esp32_common.dtsi:416 */
		wdt1: watchdog@3ff60048 {
			compatible = "espressif,esp32-watchdog"; /* in zephyr/dts/xtensa/espressif/esp32/esp32_common.dtsi:417 */
			reg = < 0x3ff60048 0x20 >;               /* in zephyr/dts/xtensa/espressif/esp32/esp32_common.dtsi:418 */
			interrupts = < 0x14 0x0 0x0 >;           /* in zephyr/dts/xtensa/espressif/esp32/esp32_common.dtsi:419 */
			interrupt-parent = < &intc >;            /* in zephyr/dts/xtensa/espressif/esp32/esp32_common.dtsi:420 */
			clocks = < &clock 0x4 >;                 /* in zephyr/dts/xtensa/espressif/esp32/esp32_common.dtsi:421 */
			status = "disabled";                     /* in zephyr/dts/xtensa/espressif/esp32/esp32_common.dtsi:422 */
		};

		/* node '/soc/spi@3ff64000' defined in zephyr/dts/xtensa/espressif/esp32/esp32_common.dtsi:425 */
		spi2: spi@3ff64000 {
			compatible = "espressif,esp32-spi"; /* in zephyr/dts/xtensa/espressif/esp32/esp32_common.dtsi:426 */
			reg = < 0x3ff64000 0x1000 >;        /* in zephyr/dts/xtensa/espressif/esp32/esp32_common.dtsi:427 */
			interrupts = < 0x1e 0x0 0x0 >;      /* in zephyr/dts/xtensa/espressif/esp32/esp32_common.dtsi:428 */
			interrupt-parent = < &intc >;       /* in zephyr/dts/xtensa/espressif/esp32/esp32_common.dtsi:429 */
			clocks = < &clock 0x7 >;            /* in zephyr/dts/xtensa/espressif/esp32/esp32_common.dtsi:430 */
			dma-clk = < 0x6e >;                 /* in zephyr/dts/xtensa/espressif/esp32/esp32_common.dtsi:431 */
			dma-host = < 0x0 >;                 /* in zephyr/dts/xtensa/espressif/esp32/esp32_common.dtsi:432 */
			#address-cells = < 0x1 >;           /* in zephyr/boards/others/doit_esp32_devkit_v1/doit_esp32_devkit_v1_procpu.dts:104 */
			#size-cells = < 0x0 >;              /* in zephyr/boards/others/doit_esp32_devkit_v1/doit_esp32_devkit_v1_procpu.dts:105 */
			status = "okay";                    /* in zephyr/boards/others/doit_esp32_devkit_v1/doit_esp32_devkit_v1_procpu.dts:106 */
			pinctrl-0 = < &spim2_default >;     /* in zephyr/boards/others/doit_esp32_devkit_v1/doit_esp32_devkit_v1_procpu.dts:107 */
			pinctrl-names = "default";          /* in zephyr/boards/others/doit_esp32_devkit_v1/doit_esp32_devkit_v1_procpu.dts:108 */
		};

		/* node '/soc/spi@3ff65000' defined in zephyr/dts/xtensa/espressif/esp32/esp32_common.dtsi:436 */
		spi3: spi@3ff65000 {
			compatible = "espressif,esp32-spi"; /* in zephyr/dts/xtensa/espressif/esp32/esp32_common.dtsi:437 */
			reg = < 0x3ff65000 0x1000 >;        /* in zephyr/dts/xtensa/espressif/esp32/esp32_common.dtsi:438 */
			interrupts = < 0x1f 0x0 0x0 >;      /* in zephyr/dts/xtensa/espressif/esp32/esp32_common.dtsi:439 */
			interrupt-parent = < &intc >;       /* in zephyr/dts/xtensa/espressif/esp32/esp32_common.dtsi:440 */
			clocks = < &clock 0x8 >;            /* in zephyr/dts/xtensa/espressif/esp32/esp32_common.dtsi:441 */
			dma-clk = < 0x6e >;                 /* in zephyr/dts/xtensa/espressif/esp32/esp32_common.dtsi:442 */
			dma-host = < 0x1 >;                 /* in zephyr/dts/xtensa/espressif/esp32/esp32_common.dtsi:443 */
			#address-cells = < 0x1 >;           /* in zephyr/boards/others/doit_esp32_devkit_v1/doit_esp32_devkit_v1_procpu.dts:112 */
			#size-cells = < 0x0 >;              /* in zephyr/boards/others/doit_esp32_devkit_v1/doit_esp32_devkit_v1_procpu.dts:113 */
			status = "okay";                    /* in zephyr/boards/others/doit_esp32_devkit_v1/doit_esp32_devkit_v1_procpu.dts:114 */
			pinctrl-0 = < &spim3_default >;     /* in zephyr/boards/others/doit_esp32_devkit_v1/doit_esp32_devkit_v1_procpu.dts:115 */
			pinctrl-names = "default";          /* in zephyr/boards/others/doit_esp32_devkit_v1/doit_esp32_devkit_v1_procpu.dts:116 */
		};

		/* node '/soc/can@3ff6b000' defined in zephyr/dts/xtensa/espressif/esp32/esp32_common.dtsi:447 */
		twai: can@3ff6b000 {
			compatible = "espressif,esp32-twai"; /* in zephyr/dts/xtensa/espressif/esp32/esp32_common.dtsi:448 */
			reg = < 0x3ff6b000 0x1000 >;         /* in zephyr/dts/xtensa/espressif/esp32/esp32_common.dtsi:449 */
			interrupts = < 0x2d 0x0 0x0 >;       /* in zephyr/dts/xtensa/espressif/esp32/esp32_common.dtsi:450 */
			interrupt-parent = < &intc >;        /* in zephyr/dts/xtensa/espressif/esp32/esp32_common.dtsi:451 */
			clocks = < &clock 0x71 >;            /* in zephyr/dts/xtensa/espressif/esp32/esp32_common.dtsi:452 */
			status = "disabled";                 /* in zephyr/dts/xtensa/espressif/esp32/esp32_common.dtsi:453 */
		};

		/* node '/soc/counter@3ff5f000' defined in zephyr/dts/xtensa/espressif/esp32/esp32_common.dtsi:456 */
		timer0: counter@3ff5f000 {
			compatible = "espressif,esp32-timer"; /* in zephyr/dts/xtensa/espressif/esp32/esp32_common.dtsi:457 */
			reg = < 0x3ff5f000 0x1000 >;          /* in zephyr/dts/xtensa/espressif/esp32/esp32_common.dtsi:458 */
			clocks = < &clock 0x3 >;              /* in zephyr/dts/xtensa/espressif/esp32/esp32_common.dtsi:459 */
			group = < 0x0 >;                      /* in zephyr/dts/xtensa/espressif/esp32/esp32_common.dtsi:460 */
			index = < 0x0 >;                      /* in zephyr/dts/xtensa/espressif/esp32/esp32_common.dtsi:461 */
			interrupts = < 0xe 0x0 0x0 >;         /* in zephyr/dts/xtensa/espressif/esp32/esp32_common.dtsi:462 */
			interrupt-parent = < &intc >;         /* in zephyr/dts/xtensa/espressif/esp32/esp32_common.dtsi:463 */
			status = "disabled";                  /* in zephyr/dts/xtensa/espressif/esp32/esp32_common.dtsi:464 */

			/* node '/soc/counter@3ff5f000/counter' defined in zephyr/dts/xtensa/espressif/esp32/esp32_common.dtsi:466 */
			counter {
				compatible = "espressif,esp32-counter"; /* in zephyr/dts/xtensa/espressif/esp32/esp32_common.dtsi:467 */
				status = "disabled";                    /* in zephyr/dts/xtensa/espressif/esp32/esp32_common.dtsi:468 */
			};
		};

		/* node '/soc/counter@3ff5f024' defined in zephyr/dts/xtensa/espressif/esp32/esp32_common.dtsi:472 */
		timer1: counter@3ff5f024 {
			compatible = "espressif,esp32-timer"; /* in zephyr/dts/xtensa/espressif/esp32/esp32_common.dtsi:473 */
			reg = < 0x3ff5f024 0x1000 >;          /* in zephyr/dts/xtensa/espressif/esp32/esp32_common.dtsi:474 */
			clocks = < &clock 0x3 >;              /* in zephyr/dts/xtensa/espressif/esp32/esp32_common.dtsi:475 */
			group = < 0x0 >;                      /* in zephyr/dts/xtensa/espressif/esp32/esp32_common.dtsi:476 */
			index = < 0x1 >;                      /* in zephyr/dts/xtensa/espressif/esp32/esp32_common.dtsi:477 */
			interrupts = < 0xf 0x0 0x0 >;         /* in zephyr/dts/xtensa/espressif/esp32/esp32_common.dtsi:478 */
			interrupt-parent = < &intc >;         /* in zephyr/dts/xtensa/espressif/esp32/esp32_common.dtsi:479 */
			status = "disabled";                  /* in zephyr/dts/xtensa/espressif/esp32/esp32_common.dtsi:480 */

			/* node '/soc/counter@3ff5f024/counter' defined in zephyr/dts/xtensa/espressif/esp32/esp32_common.dtsi:482 */
			counter {
				compatible = "espressif,esp32-counter"; /* in zephyr/dts/xtensa/espressif/esp32/esp32_common.dtsi:483 */
				status = "disabled";                    /* in zephyr/dts/xtensa/espressif/esp32/esp32_common.dtsi:484 */
			};
		};

		/* node '/soc/counter@3ff60000' defined in zephyr/dts/xtensa/espressif/esp32/esp32_common.dtsi:488 */
		timer2: counter@3ff60000 {
			compatible = "espressif,esp32-timer"; /* in zephyr/dts/xtensa/espressif/esp32/esp32_common.dtsi:489 */
			reg = < 0x3ff60000 0x1000 >;          /* in zephyr/dts/xtensa/espressif/esp32/esp32_common.dtsi:490 */
			clocks = < &clock 0x4 >;              /* in zephyr/dts/xtensa/espressif/esp32/esp32_common.dtsi:491 */
			group = < 0x1 >;                      /* in zephyr/dts/xtensa/espressif/esp32/esp32_common.dtsi:492 */
			index = < 0x0 >;                      /* in zephyr/dts/xtensa/espressif/esp32/esp32_common.dtsi:493 */
			interrupts = < 0x12 0x0 0x0 >;        /* in zephyr/dts/xtensa/espressif/esp32/esp32_common.dtsi:494 */
			interrupt-parent = < &intc >;         /* in zephyr/dts/xtensa/espressif/esp32/esp32_common.dtsi:495 */
			status = "disabled";                  /* in zephyr/dts/xtensa/espressif/esp32/esp32_common.dtsi:496 */

			/* node '/soc/counter@3ff60000/counter' defined in zephyr/dts/xtensa/espressif/esp32/esp32_common.dtsi:498 */
			counter {
				compatible = "espressif,esp32-counter"; /* in zephyr/dts/xtensa/espressif/esp32/esp32_common.dtsi:499 */
				status = "disabled";                    /* in zephyr/dts/xtensa/espressif/esp32/esp32_common.dtsi:500 */
			};
		};

		/* node '/soc/counter@3ff60024' defined in zephyr/dts/xtensa/espressif/esp32/esp32_common.dtsi:504 */
		timer3: counter@3ff60024 {
			compatible = "espressif,esp32-timer"; /* in zephyr/dts/xtensa/espressif/esp32/esp32_common.dtsi:505 */
			reg = < 0x3ff60024 0x1000 >;          /* in zephyr/dts/xtensa/espressif/esp32/esp32_common.dtsi:506 */
			clocks = < &clock 0x4 >;              /* in zephyr/dts/xtensa/espressif/esp32/esp32_common.dtsi:507 */
			group = < 0x1 >;                      /* in zephyr/dts/xtensa/espressif/esp32/esp32_common.dtsi:508 */
			index = < 0x1 >;                      /* in zephyr/dts/xtensa/espressif/esp32/esp32_common.dtsi:509 */
			interrupts = < 0x13 0x0 0x0 >;        /* in zephyr/dts/xtensa/espressif/esp32/esp32_common.dtsi:510 */
			interrupt-parent = < &intc >;         /* in zephyr/dts/xtensa/espressif/esp32/esp32_common.dtsi:511 */
			status = "disabled";                  /* in zephyr/dts/xtensa/espressif/esp32/esp32_common.dtsi:512 */

			/* node '/soc/counter@3ff60024/counter' defined in zephyr/dts/xtensa/espressif/esp32/esp32_common.dtsi:514 */
			counter {
				compatible = "espressif,esp32-counter"; /* in zephyr/dts/xtensa/espressif/esp32/esp32_common.dtsi:515 */
				status = "disabled";                    /* in zephyr/dts/xtensa/espressif/esp32/esp32_common.dtsi:516 */
			};
		};

		/* node '/soc/dac@3ff48800' defined in zephyr/dts/xtensa/espressif/esp32/esp32_common.dtsi:520 */
		dac: dac@3ff48800 {
			compatible = "espressif,esp32-dac"; /* in zephyr/dts/xtensa/espressif/esp32/esp32_common.dtsi:521 */
			reg = < 0x3ff48800 0x100 >;         /* in zephyr/dts/xtensa/espressif/esp32/esp32_common.dtsi:522 */
			interrupts = < 0x2e 0x0 0x0 >;      /* in zephyr/dts/xtensa/espressif/esp32/esp32_common.dtsi:523 */
			interrupt-parent = < &intc >;       /* in zephyr/dts/xtensa/espressif/esp32/esp32_common.dtsi:524 */
			clocks = < &clock 0x76 >;           /* in zephyr/dts/xtensa/espressif/esp32/esp32_common.dtsi:525 */
			#io-channel-cells = < 0x1 >;        /* in zephyr/dts/xtensa/espressif/esp32/esp32_common.dtsi:526 */
			status = "disabled";                /* in zephyr/dts/xtensa/espressif/esp32/esp32_common.dtsi:527 */
		};

		/* node '/soc/adc@3ff48800' defined in zephyr/dts/xtensa/espressif/esp32/esp32_common.dtsi:530 */
		adc0: adc@3ff48800 {
			compatible = "espressif,esp32-adc"; /* in zephyr/dts/xtensa/espressif/esp32/esp32_common.dtsi:531 */
			reg = < 0x3ff48800 0xa >;           /* in zephyr/dts/xtensa/espressif/esp32/esp32_common.dtsi:532 */
			clocks = < &clock 0x76 >;           /* in zephyr/dts/xtensa/espressif/esp32/esp32_common.dtsi:533 */
			interrupt-parent = < &intc >;       /* in zephyr/dts/xtensa/espressif/esp32/esp32_common.dtsi:534 */
			unit = < 0x1 >;                     /* in zephyr/dts/xtensa/espressif/esp32/esp32_common.dtsi:535 */
			channel-count = < 0x8 >;            /* in zephyr/dts/xtensa/espressif/esp32/esp32_common.dtsi:536 */
			#io-channel-cells = < 0x1 >;        /* in zephyr/dts/xtensa/espressif/esp32/esp32_common.dtsi:537 */
			status = "disabled";                /* in zephyr/dts/xtensa/espressif/esp32/esp32_common.dtsi:538 */
		};

		/* node '/soc/adc@3ff48890' defined in zephyr/dts/xtensa/espressif/esp32/esp32_common.dtsi:541 */
		adc1: adc@3ff48890 {
			compatible = "espressif,esp32-adc"; /* in zephyr/dts/xtensa/espressif/esp32/esp32_common.dtsi:542 */
			reg = < 0x3ff48890 0xa >;           /* in zephyr/dts/xtensa/espressif/esp32/esp32_common.dtsi:543 */
			clocks = < &clock 0x76 >;           /* in zephyr/dts/xtensa/espressif/esp32/esp32_common.dtsi:544 */
			unit = < 0x2 >;                     /* in zephyr/dts/xtensa/espressif/esp32/esp32_common.dtsi:545 */
			channel-count = < 0xa >;            /* in zephyr/dts/xtensa/espressif/esp32/esp32_common.dtsi:546 */
			#io-channel-cells = < 0x1 >;        /* in zephyr/dts/xtensa/espressif/esp32/esp32_common.dtsi:547 */
			status = "disabled";                /* in zephyr/dts/xtensa/espressif/esp32/esp32_common.dtsi:548 */
		};

		/* node '/soc/sdhc@3ff68000' defined in zephyr/dts/xtensa/espressif/esp32/esp32_common.dtsi:551 */
		sdhc: sdhc@3ff68000 {
			compatible = "espressif,esp32-sdhc"; /* in zephyr/dts/xtensa/espressif/esp32/esp32_common.dtsi:552 */
			reg = < 0x3ff68000 0x1000 >;         /* in zephyr/dts/xtensa/espressif/esp32/esp32_common.dtsi:553 */
			interrupts = < 0x25 0x0 0x0 >;       /* in zephyr/dts/xtensa/espressif/esp32/esp32_common.dtsi:554 */
			interrupt-parent = < &intc >;        /* in zephyr/dts/xtensa/espressif/esp32/esp32_common.dtsi:555 */
			clocks = < &clock 0x6f >;            /* in zephyr/dts/xtensa/espressif/esp32/esp32_common.dtsi:556 */
			#address-cells = < 0x1 >;            /* in zephyr/dts/xtensa/espressif/esp32/esp32_common.dtsi:557 */
			#size-cells = < 0x0 >;               /* in zephyr/dts/xtensa/espressif/esp32/esp32_common.dtsi:558 */

			/* node '/soc/sdhc@3ff68000/sdhc@0' defined in zephyr/dts/xtensa/espressif/esp32/esp32_common.dtsi:560 */
			sdhc0: sdhc@0 {
				compatible = "espressif,esp32-sdhc-slot"; /* in zephyr/dts/xtensa/espressif/esp32/esp32_common.dtsi:561 */
				reg = < 0x0 >;                            /* in zephyr/dts/xtensa/espressif/esp32/esp32_common.dtsi:562 */
				status = "disabled";                      /* in zephyr/dts/xtensa/espressif/esp32/esp32_common.dtsi:563 */
			};

			/* node '/soc/sdhc@3ff68000/sdhc@1' defined in zephyr/dts/xtensa/espressif/esp32/esp32_common.dtsi:566 */
			sdhc1: sdhc@1 {
				compatible = "espressif,esp32-sdhc-slot"; /* in zephyr/dts/xtensa/espressif/esp32/esp32_common.dtsi:567 */
				reg = < 0x1 >;                            /* in zephyr/dts/xtensa/espressif/esp32/esp32_common.dtsi:568 */
				status = "disabled";                      /* in zephyr/dts/xtensa/espressif/esp32/esp32_common.dtsi:569 */
			};
		};

		/* node '/soc/sha@3ff03000' defined in zephyr/dts/xtensa/espressif/esp32/esp32_common.dtsi:573 */
		sha: sha@3ff03000 {
			compatible = "espressif,esp32-sha"; /* in zephyr/dts/xtensa/espressif/esp32/esp32_common.dtsi:574 */
			reg = < 0x3ff03000 0x100 >;         /* in zephyr/dts/xtensa/espressif/esp32/esp32_common.dtsi:575 */
			clocks = < &clock 0x74 >;           /* in zephyr/dts/xtensa/espressif/esp32/esp32_common.dtsi:576 */
			status = "okay";                    /* in zephyr/dts/xtensa/espressif/esp32/esp32_common.dtsi:577 */
		};

		/* node '/soc/aes@3ff01000' defined in zephyr/dts/xtensa/espressif/esp32/esp32_common.dtsi:580 */
		aes: aes@3ff01000 {
			compatible = "espressif,esp32-aes"; /* in zephyr/dts/xtensa/espressif/esp32/esp32_common.dtsi:581 */
			reg = < 0x3ff01000 0x1000 >;        /* in zephyr/dts/xtensa/espressif/esp32/esp32_common.dtsi:582 */
			clocks = < &clock 0x73 >;           /* in zephyr/dts/xtensa/espressif/esp32/esp32_common.dtsi:583 */
			status = "okay";                    /* in zephyr/dts/xtensa/espressif/esp32/esp32_common.dtsi:584 */
		};
	};

	/* node '/cpus' defined in zephyr/dts/xtensa/espressif/esp32/esp32_common.dtsi:26 */
	cpus {
		#address-cells = < 0x1 >; /* in zephyr/dts/xtensa/espressif/esp32/esp32_common.dtsi:27 */
		#size-cells = < 0x0 >;    /* in zephyr/dts/xtensa/espressif/esp32/esp32_common.dtsi:28 */

		/* node '/cpus/cpu@0' defined in zephyr/dts/xtensa/espressif/esp32/esp32_common.dtsi:30 */
		cpu0: cpu@0 {
			device_type = "cpu";                             /* in zephyr/dts/xtensa/espressif/esp32/esp32_common.dtsi:31 */
			compatible = "espressif,xtensa-lx6";             /* in zephyr/dts/xtensa/espressif/esp32/esp32_common.dtsi:32 */
			reg = < 0x0 >;                                   /* in zephyr/dts/xtensa/espressif/esp32/esp32_common.dtsi:33 */
			cpu-power-states = < &light_sleep &deep_sleep >; /* in zephyr/dts/xtensa/espressif/esp32/esp32_common.dtsi:34 */
			clock-source = < 0x1 >;                          /* in zephyr/dts/xtensa/espressif/esp32/esp32_common.dtsi:35 */
			clock-frequency = < 0xe4e1c00 >;                 /* in zephyr/dts/xtensa/espressif/esp32/esp32_common.dtsi:36 */
			xtal-freq = < 0x2625a00 >;                       /* in zephyr/dts/xtensa/espressif/esp32/esp32_common.dtsi:37 */
		};

		/* node '/cpus/cpu@1' defined in zephyr/dts/xtensa/espressif/esp32/esp32_common.dtsi:40 */
		cpu1: cpu@1 {
			device_type = "cpu";                 /* in zephyr/dts/xtensa/espressif/esp32/esp32_common.dtsi:41 */
			compatible = "espressif,xtensa-lx6"; /* in zephyr/dts/xtensa/espressif/esp32/esp32_common.dtsi:42 */
			reg = < 0x1 >;                       /* in zephyr/dts/xtensa/espressif/esp32/esp32_common.dtsi:43 */
			clock-source = < 0x1 >;              /* in zephyr/dts/xtensa/espressif/esp32/esp32_common.dtsi:44 */
			clock-frequency = < 0xe4e1c00 >;     /* in zephyr/dts/xtensa/espressif/esp32/esp32_common.dtsi:45 */
			xtal-freq = < 0x2625a00 >;           /* in zephyr/dts/xtensa/espressif/esp32/esp32_common.dtsi:46 */
		};

		/* node '/cpus/power-states' defined in zephyr/dts/xtensa/espressif/esp32/esp32_common.dtsi:49 */
		power-states {

			/* node '/cpus/power-states/light_sleep' defined in zephyr/dts/xtensa/espressif/esp32/esp32_common.dtsi:50 */
			light_sleep: light_sleep {
				compatible = "zephyr,power-state"; /* in zephyr/dts/xtensa/espressif/esp32/esp32_common.dtsi:51 */
				power-state-name = "standby";      /* in zephyr/dts/xtensa/espressif/esp32/esp32_common.dtsi:52 */
				min-residency-us = < 0x3e8 >;      /* in zephyr/dts/xtensa/espressif/esp32/esp32_common.dtsi:53 */
				exit-latency-us = < 0x32 >;        /* in zephyr/dts/xtensa/espressif/esp32/esp32_common.dtsi:54 */
				phandle = < 0xc >;                 /* in zephyr/dts/xtensa/espressif/esp32/esp32_common.dtsi:34 */
			};

			/* node '/cpus/power-states/deep_sleep' defined in zephyr/dts/xtensa/espressif/esp32/esp32_common.dtsi:57 */
			deep_sleep: deep_sleep {
				compatible = "zephyr,power-state"; /* in zephyr/dts/xtensa/espressif/esp32/esp32_common.dtsi:61 */
				power-state-name = "soft-off";     /* in zephyr/dts/xtensa/espressif/esp32/esp32_common.dtsi:62 */
				status = "disabled";               /* in zephyr/dts/xtensa/espressif/esp32/esp32_common.dtsi:63 */
				phandle = < 0xd >;                 /* in zephyr/dts/xtensa/espressif/esp32/esp32_common.dtsi:34 */
			};
		};
	};

	/* node '/wifi' defined in zephyr/dts/xtensa/espressif/esp32/esp32_common.dtsi:68 */
	wifi: wifi {
		compatible = "espressif,esp32-wifi"; /* in zephyr/dts/xtensa/espressif/esp32/esp32_common.dtsi:69 */
		status = "okay";                     /* in zephyr/boards/others/doit_esp32_devkit_v1/doit_esp32_devkit_v1_procpu.dts:128 */
	};

	/* node '/esp32_bt_hci' defined in zephyr/dts/xtensa/espressif/esp32/esp32_common.dtsi:73 */
	esp32_bt_hci: esp32_bt_hci {
		compatible = "espressif,esp32-bt-hci"; /* in zephyr/dts/xtensa/espressif/esp32/esp32_common.dtsi:74 */
		bt-hci-vs-ext;                         /* in zephyr/dts/xtensa/espressif/esp32/esp32_common.dtsi:75 */
		status = "okay";                       /* in zephyr/boards/others/doit_esp32_devkit_v1/doit_esp32_devkit_v1_procpu.dts:124 */
	};

	/* node '/eth' defined in zephyr/dts/xtensa/espressif/esp32/esp32_common.dtsi:79 */
	eth: eth {
		compatible = "espressif,esp32-eth"; /* in zephyr/dts/xtensa/espressif/esp32/esp32_common.dtsi:80 */
		interrupts = < 0x26 0x0 0x0 >;      /* in zephyr/dts/xtensa/espressif/esp32/esp32_common.dtsi:81 */
		interrupt-parent = < &intc >;       /* in zephyr/dts/xtensa/espressif/esp32/esp32_common.dtsi:82 */
		clocks = < &clock 0x72 >;           /* in zephyr/dts/xtensa/espressif/esp32/esp32_common.dtsi:83 */
		status = "disabled";                /* in zephyr/dts/xtensa/espressif/esp32/esp32_common.dtsi:84 */
	};

	/* node '/mdio' defined in zephyr/dts/xtensa/espressif/esp32/esp32_common.dtsi:87 */
	mdio: mdio {
		compatible = "espressif,esp32-mdio"; /* in zephyr/dts/xtensa/espressif/esp32/esp32_common.dtsi:88 */
		clocks = < &clock 0x72 >;            /* in zephyr/dts/xtensa/espressif/esp32/esp32_common.dtsi:89 */
		status = "disabled";                 /* in zephyr/dts/xtensa/espressif/esp32/esp32_common.dtsi:90 */
		#address-cells = < 0x1 >;            /* in zephyr/dts/xtensa/espressif/esp32/esp32_common.dtsi:91 */
		#size-cells = < 0x0 >;               /* in zephyr/dts/xtensa/espressif/esp32/esp32_common.dtsi:92 */
	};

	/* node '/pin-controller' defined in zephyr/dts/xtensa/espressif/esp32/esp32_common.dtsi:95 */
	pinctrl: pin-controller {
		compatible = "espressif,esp32-pinctrl"; /* in zephyr/dts/xtensa/espressif/esp32/esp32_common.dtsi:96 */
		status = "okay";                        /* in zephyr/dts/xtensa/espressif/esp32/esp32_common.dtsi:97 */

		/* node '/pin-controller/uart0_default' defined in zephyr/boards/others/doit_esp32_devkit_v1/doit_esp32_devkit_v1-pinctrl.dtsi:12 */
		uart0_default: uart0_default {
			phandle = < 0x4 >; /* in zephyr/boards/others/doit_esp32_devkit_v1/doit_esp32_devkit_v1_procpu.dts:58 */

			/* node '/pin-controller/uart0_default/group1' defined in zephyr/boards/others/doit_esp32_devkit_v1/doit_esp32_devkit_v1-pinctrl.dtsi:13 */
			group1 {
				pinmux = < 0x77fc1 >; /* in zephyr/boards/others/doit_esp32_devkit_v1/doit_esp32_devkit_v1-pinctrl.dtsi:14 */
				output-high;          /* in zephyr/boards/others/doit_esp32_devkit_v1/doit_esp32_devkit_v1-pinctrl.dtsi:15 */
			};

			/* node '/pin-controller/uart0_default/group2' defined in zephyr/boards/others/doit_esp32_devkit_v1/doit_esp32_devkit_v1-pinctrl.dtsi:18 */
			group2 {
				pinmux = < 0xff8383 >; /* in zephyr/boards/others/doit_esp32_devkit_v1/doit_esp32_devkit_v1-pinctrl.dtsi:19 */
				bias-pull-up;          /* in zephyr/boards/others/doit_esp32_devkit_v1/doit_esp32_devkit_v1-pinctrl.dtsi:20 */
			};
		};

		/* node '/pin-controller/uart2_default' defined in zephyr/boards/others/doit_esp32_devkit_v1/doit_esp32_devkit_v1-pinctrl.dtsi:24 */
		uart2_default: uart2_default {
			phandle = < 0x5 >; /* in zephyr/boards/others/doit_esp32_devkit_v1/doit_esp32_devkit_v1_procpu.dts:64 */

			/* node '/pin-controller/uart2_default/group1' defined in zephyr/boards/others/doit_esp32_devkit_v1/doit_esp32_devkit_v1-pinctrl.dtsi:25 */
			group1 {
				pinmux = < 0x637fd1 >; /* in zephyr/boards/others/doit_esp32_devkit_v1/doit_esp32_devkit_v1-pinctrl.dtsi:26 */
			};

			/* node '/pin-controller/uart2_default/group2' defined in zephyr/boards/others/doit_esp32_devkit_v1/doit_esp32_devkit_v1-pinctrl.dtsi:29 */
			group2 {
				pinmux = < 0xffb190 >; /* in zephyr/boards/others/doit_esp32_devkit_v1/doit_esp32_devkit_v1-pinctrl.dtsi:30 */
				bias-pull-up;          /* in zephyr/boards/others/doit_esp32_devkit_v1/doit_esp32_devkit_v1-pinctrl.dtsi:31 */
			};
		};

		/* node '/pin-controller/spim2_default' defined in zephyr/boards/others/doit_esp32_devkit_v1/doit_esp32_devkit_v1-pinctrl.dtsi:35 */
		spim2_default: spim2_default {
			phandle = < 0xa >; /* in zephyr/boards/others/doit_esp32_devkit_v1/doit_esp32_devkit_v1_procpu.dts:107 */

			/* node '/pin-controller/spim2_default/group1' defined in zephyr/boards/others/doit_esp32_devkit_v1/doit_esp32_devkit_v1-pinctrl.dtsi:36 */
			group1 {
				pinmux = < 0xff824c >,
				         < 0x47fce >,
				         < 0x5ffcf >;  /* in zephyr/boards/others/doit_esp32_devkit_v1/doit_esp32_devkit_v1-pinctrl.dtsi:37 */
			};

			/* node '/pin-controller/spim2_default/group2' defined in zephyr/boards/others/doit_esp32_devkit_v1/doit_esp32_devkit_v1-pinctrl.dtsi:42 */
			group2 {
				pinmux = < 0x57fcd >; /* in zephyr/boards/others/doit_esp32_devkit_v1/doit_esp32_devkit_v1-pinctrl.dtsi:43 */
				output-low;           /* in zephyr/boards/others/doit_esp32_devkit_v1/doit_esp32_devkit_v1-pinctrl.dtsi:44 */
			};
		};

		/* node '/pin-controller/spim3_default' defined in zephyr/boards/others/doit_esp32_devkit_v1/doit_esp32_devkit_v1-pinctrl.dtsi:48 */
		spim3_default: spim3_default {
			phandle = < 0xb >; /* in zephyr/boards/others/doit_esp32_devkit_v1/doit_esp32_devkit_v1_procpu.dts:115 */

			/* node '/pin-controller/spim3_default/group1' defined in zephyr/boards/others/doit_esp32_devkit_v1/doit_esp32_devkit_v1-pinctrl.dtsi:49 */
			group1 {
				pinmux = < 0xff9013 >,
				         < 0x1fffd2 >,
				         < 0x227fc5 >; /* in zephyr/boards/others/doit_esp32_devkit_v1/doit_esp32_devkit_v1-pinctrl.dtsi:50 */
			};

			/* node '/pin-controller/spim3_default/group2' defined in zephyr/boards/others/doit_esp32_devkit_v1/doit_esp32_devkit_v1-pinctrl.dtsi:55 */
			group2 {
				pinmux = < 0x20ffd7 >; /* in zephyr/boards/others/doit_esp32_devkit_v1/doit_esp32_devkit_v1-pinctrl.dtsi:56 */
				output-low;            /* in zephyr/boards/others/doit_esp32_devkit_v1/doit_esp32_devkit_v1-pinctrl.dtsi:57 */
			};
		};

		/* node '/pin-controller/i2c0_default' defined in zephyr/boards/others/doit_esp32_devkit_v1/doit_esp32_devkit_v1-pinctrl.dtsi:61 */
		i2c0_default: i2c0_default {
			phandle = < 0x8 >; /* in zephyr/boards/others/doit_esp32_devkit_v1/doit_esp32_devkit_v1_procpu.dts:93 */

			/* node '/pin-controller/i2c0_default/group1' defined in zephyr/boards/others/doit_esp32_devkit_v1/doit_esp32_devkit_v1-pinctrl.dtsi:62 */
			group1 {
				pinmux = < 0xf0795 >,
				         < 0xe8756 >; /* in zephyr/boards/others/doit_esp32_devkit_v1/doit_esp32_devkit_v1-pinctrl.dtsi:63 */
				bias-pull-up;         /* in zephyr/boards/others/doit_esp32_devkit_v1/doit_esp32_devkit_v1-pinctrl.dtsi:65 */
				drive-open-drain;     /* in zephyr/boards/others/doit_esp32_devkit_v1/doit_esp32_devkit_v1-pinctrl.dtsi:66 */
				output-high;          /* in zephyr/boards/others/doit_esp32_devkit_v1/doit_esp32_devkit_v1-pinctrl.dtsi:67 */
			};
		};

		/* node '/pin-controller/i2s0_default' defined in zephyr/boards/others/doit_esp32_devkit_v1/doit_esp32_devkit_v1-pinctrl.dtsi:71 */
		i2s0_default: i2s0_default {
			phandle = < 0x9 >; /* in zephyr/boards/others/doit_esp32_devkit_v1/doit_esp32_devkit_v1_procpu.dts:98 */

			/* node '/pin-controller/i2s0_default/group1' defined in zephyr/boards/others/doit_esp32_devkit_v1/doit_esp32_devkit_v1-pinctrl.dtsi:72 */
			group1 {
				pinmux = < 0xc8659 >,
				         < 0xb85da >,
				         < 0x51ffdb >,
				         < 0xe0721 >,
				         < 0xd86e0 >;  /* in zephyr/boards/others/doit_esp32_devkit_v1/doit_esp32_devkit_v1-pinctrl.dtsi:73 */
				output-enable;         /* in zephyr/boards/others/doit_esp32_devkit_v1/doit_esp32_devkit_v1-pinctrl.dtsi:78 */
			};

			/* node '/pin-controller/i2s0_default/group2' defined in zephyr/boards/others/doit_esp32_devkit_v1/doit_esp32_devkit_v1-pinctrl.dtsi:81 */
			group2 {
				pinmux = < 0xffa6e3 >; /* in zephyr/boards/others/doit_esp32_devkit_v1/doit_esp32_devkit_v1-pinctrl.dtsi:82 */
				input-enable;          /* in zephyr/boards/others/doit_esp32_devkit_v1/doit_esp32_devkit_v1-pinctrl.dtsi:83 */
			};
		};
	};

	/* node '/clock' defined in zephyr/dts/xtensa/espressif/esp32/esp32_common.dtsi:100 */
	clock: clock {
		compatible = "espressif,esp32-clock"; /* in zephyr/dts/xtensa/espressif/esp32/esp32_common.dtsi:101 */
		fast-clk-src = < 0x1 >;               /* in zephyr/dts/xtensa/espressif/esp32/esp32_common.dtsi:102 */
		slow-clk-src = < 0x0 >;               /* in zephyr/dts/xtensa/espressif/esp32/esp32_common.dtsi:103 */
		#clock-cells = < 0x1 >;               /* in zephyr/dts/xtensa/espressif/esp32/esp32_common.dtsi:104 */
		status = "okay";                      /* in zephyr/dts/xtensa/espressif/esp32/esp32_common.dtsi:105 */
		phandle = < 0x3 >;                    /* in zephyr/dts/xtensa/espressif/esp32/esp32_common.dtsi:207 */
	};

	/* node '/leds' defined in zephyr/boards/others/doit_esp32_devkit_v1/doit_esp32_devkit_v1_procpu.dts:26 */
	leds {
		compatible = "gpio-leds"; /* in zephyr/boards/others/doit_esp32_devkit_v1/doit_esp32_devkit_v1_procpu.dts:27 */

		/* node '/leds/blue_led' defined in zephyr/boards/others/doit_esp32_devkit_v1/doit_esp32_devkit_v1_procpu.dts:29 */
		blue_led: blue_led {
			gpios = < &gpio0 0x2 0x0 >; /* in zephyr/boards/others/doit_esp32_devkit_v1/doit_esp32_devkit_v1_procpu.dts:30 */
			label = "User LED";         /* in zephyr/boards/others/doit_esp32_devkit_v1/doit_esp32_devkit_v1_procpu.dts:31 */
		};
	};

	/* node '/buttons' defined in zephyr/boards/others/doit_esp32_devkit_v1/doit_esp32_devkit_v1_procpu.dts:35 */
	buttons {
		compatible = "gpio-keys"; /* in zephyr/boards/others/doit_esp32_devkit_v1/doit_esp32_devkit_v1_procpu.dts:36 */

		/* node '/buttons/button_0' defined in zephyr/boards/others/doit_esp32_devkit_v1/doit_esp32_devkit_v1_procpu.dts:38 */
		button0: button_0 {
			gpios = < &gpio0 0x0 0x11 >; /* in zephyr/boards/others/doit_esp32_devkit_v1/doit_esp32_devkit_v1_procpu.dts:39 */
			label = "BOOT Button";       /* in zephyr/boards/others/doit_esp32_devkit_v1/doit_esp32_devkit_v1_procpu.dts:40 */
			zephyr,code = < 0xb >;       /* in zephyr/boards/others/doit_esp32_devkit_v1/doit_esp32_devkit_v1_procpu.dts:41 */
		};
	};
};
